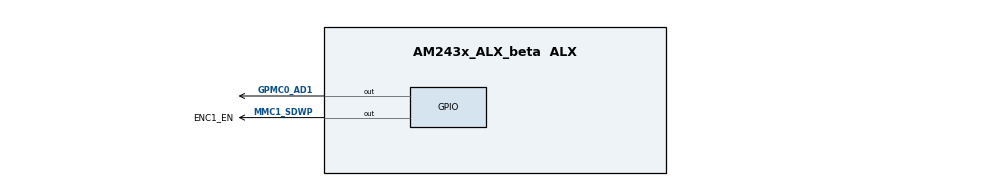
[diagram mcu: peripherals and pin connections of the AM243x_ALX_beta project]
/**
 * @cliArgs --device "AM243x_ALX_beta" --package "ALX" --part "ALX" --context "r5fss0-0" --product "MOTOR_CONTROL_SDK@09.00.00"
 * @versions {"tool":"1.17.0+3128"}
 */

/**
 * Import the modules used in this configuration.
 */
const gpio       = scripting.addModule("/drivers/gpio/gpio", {}, false);
const gpio1      = gpio.addInstance();
const gpio2      = gpio.addInstance();
const i2c        = scripting.addModule("/drivers/i2c/i2c", {}, false);
const i2c1       = i2c.addInstance();
const pruicss    = scripting.addModule("/drivers/pruicss/pruicss", {}, false);
const pruicss1   = pruicss.addInstance();
const udma       = scripting.addModule("/drivers/udma/udma", {}, false);
const udma1      = udma.addInstance();
const debug_log  = scripting.addModule("/kernel/dpl/debug_log");
const mpu_armv7  = scripting.addModule("/kernel/dpl/mpu_armv7", {}, false);
const mpu_armv71 = mpu_armv7.addInstance();
const mpu_armv72 = mpu_armv7.addInstance();
const mpu_armv73 = mpu_armv7.addInstance();
const mpu_armv74 = mpu_armv7.addInstance();
const mpu_armv75 = mpu_armv7.addInstance();
const hdsl       = scripting.addModule("/position_sense/hdsl", {}, false);
const hdsl1      = hdsl.addInstance();

/**
 * Write custom configuration values to the imported modules.
 */
gpio1.$name                = "CONFIG_GPIO0";
gpio1.pinDir               = "OUTPUT";
gpio1.GPIO.gpioPin.rx      = false;
gpio1.GPIO.gpioPin.$assign = "GPMC0_AD1";

i2c1.$name       = "CONFIG_I2C0";
i2c1.I2C.$assign = "I2C1";

pruicss1.$name                           = "CONFIG_PRU_ICSS1";
pruicss1.instance                        = "ICSSG1";
pruicss1.AdditionalICSSSettings[0].$name = "CONFIG_PRU_ICSS_IO1";

udma1.$name                                     = "CONFIG_UDMA0";
udma1.udmaBlkCopyChannel.create(1);
udma1.udmaBlkCopyChannel[0].$name               = "CONFIG_UDMA_BLKCOPY_CH0";
udma1.udmaBlkCopyChannel[0].transferCallbackFxn = "App_udmaEventCb";

debug_log.enableUartLog        = true;
debug_log.enableCssLog         = false;
debug_log.uartLog.$name        = "CONFIG_UART_CONSOLE";
debug_log.uartLog.UART.$assign = "USART0";

mpu_armv71.$name             = "CONFIG_MPU_REGION0";
mpu_armv71.size              = 31;
mpu_armv71.attributes        = "Device";
mpu_armv71.accessPermissions = "Supervisor RD+WR, User RD";
mpu_armv71.allowExecute      = false;

mpu_armv72.$name             = "CONFIG_MPU_REGION1";
mpu_armv72.size              = 15;
mpu_armv72.accessPermissions = "Supervisor RD+WR, User RD";

mpu_armv73.$name             = "CONFIG_MPU_REGION2";
mpu_armv73.baseAddr          = 0x41010000;
mpu_armv73.size              = 15;
mpu_armv73.accessPermissions = "Supervisor RD+WR, User RD";

mpu_armv74.$name             = "CONFIG_MPU_REGION3";
mpu_armv74.accessPermissions = "Supervisor RD+WR, User RD";
mpu_armv74.baseAddr          = 0x70000000;
mpu_armv74.size              = 21;

mpu_armv75.$name             = "CONFIG_MPU_REGION4";
mpu_armv75.baseAddr          = 0x60000000;
mpu_armv75.size              = 28;
mpu_armv75.accessPermissions = "Supervisor RD, User RD";

hdsl1.$name                      = "CONFIG_HDSL0";
hdsl1.Booster_Pack               = true;
hdsl1.coreClk                    = 300000000;
hdsl1.PRU_ICSSG0_PRU.$assign     = "PRU_ICSSG0_PRU1";
hdsl1.PRU_ICSSG0_PRU.GPO5.$used  = false;
hdsl1.PRU_ICSSG0_PRU.GPO4.$used  = false;
hdsl1.PRU_ICSSG0_PRU.GPO3.$used  = false;
hdsl1.PRU_ICSSG0_PRU.GPI14.$used = false;
hdsl1.PRU_ICSSG0_PRU.GPO8.$used  = false;
hdsl1.PRU_ICSSG0_PRU.GPO12.$used = false;
hdsl1.PRU_ICSSG0_PRU.GPO6.$used  = false;
hdsl1.PRU_ICSSG0_PRU.GPI11.$used = false;

hdsl1.ENC1_EN              = gpio2;
gpio2.$name                = "ENC1_EN";
gpio2.GPIO.$assign         = "GPIO1";
gpio2.GPIO.gpioPin.rx      = false;
gpio2.GPIO.gpioPin.$assign = "MMC1_SDWP";

const pruicss2                           = pruicss.addInstance({}, false);
pruicss2.$name                           = "CONFIG_PRU_ICSS0";
hdsl1.pru                                = pruicss2;
pruicss2.AdditionalICSSSettings[0].$name = "CONFIG_PRU_ICSS_IO0";

/**
 * Pinmux solution for unlocked pins/peripherals. This ensures that minor changes to the automatic solver in a future
 * version of the tool will not impact the pinmux you originally saw.  These lines can be completely deleted in order to
 * re-solve from scratch.
 */
gpio1.GPIO.$suggestSolution                 = "GPIO0";
i2c1.I2C.SCL.$suggestSolution               = "I2C1_SCL";
i2c1.I2C.SDA.$suggestSolution               = "I2C1_SDA";
debug_log.uartLog.UART.RXD.$suggestSolution = "UART0_RXD";
debug_log.uartLog.UART.TXD.$suggestSolution = "UART0_TXD";
hdsl1.PRU_ICSSG0_PRU.GPO2.$suggestSolution  = "PRG0_PRU1_GPO2";
hdsl1.PRU_ICSSG0_PRU.GPO1.$suggestSolution  = "PRG0_PRU1_GPO1";
hdsl1.PRU_ICSSG0_PRU.GPO0.$suggestSolution  = "PRG0_PRU1_GPO0";
hdsl1.PRU_ICSSG0_PRU.GPI13.$suggestSolution = "PRG0_PRU1_GPO13";
